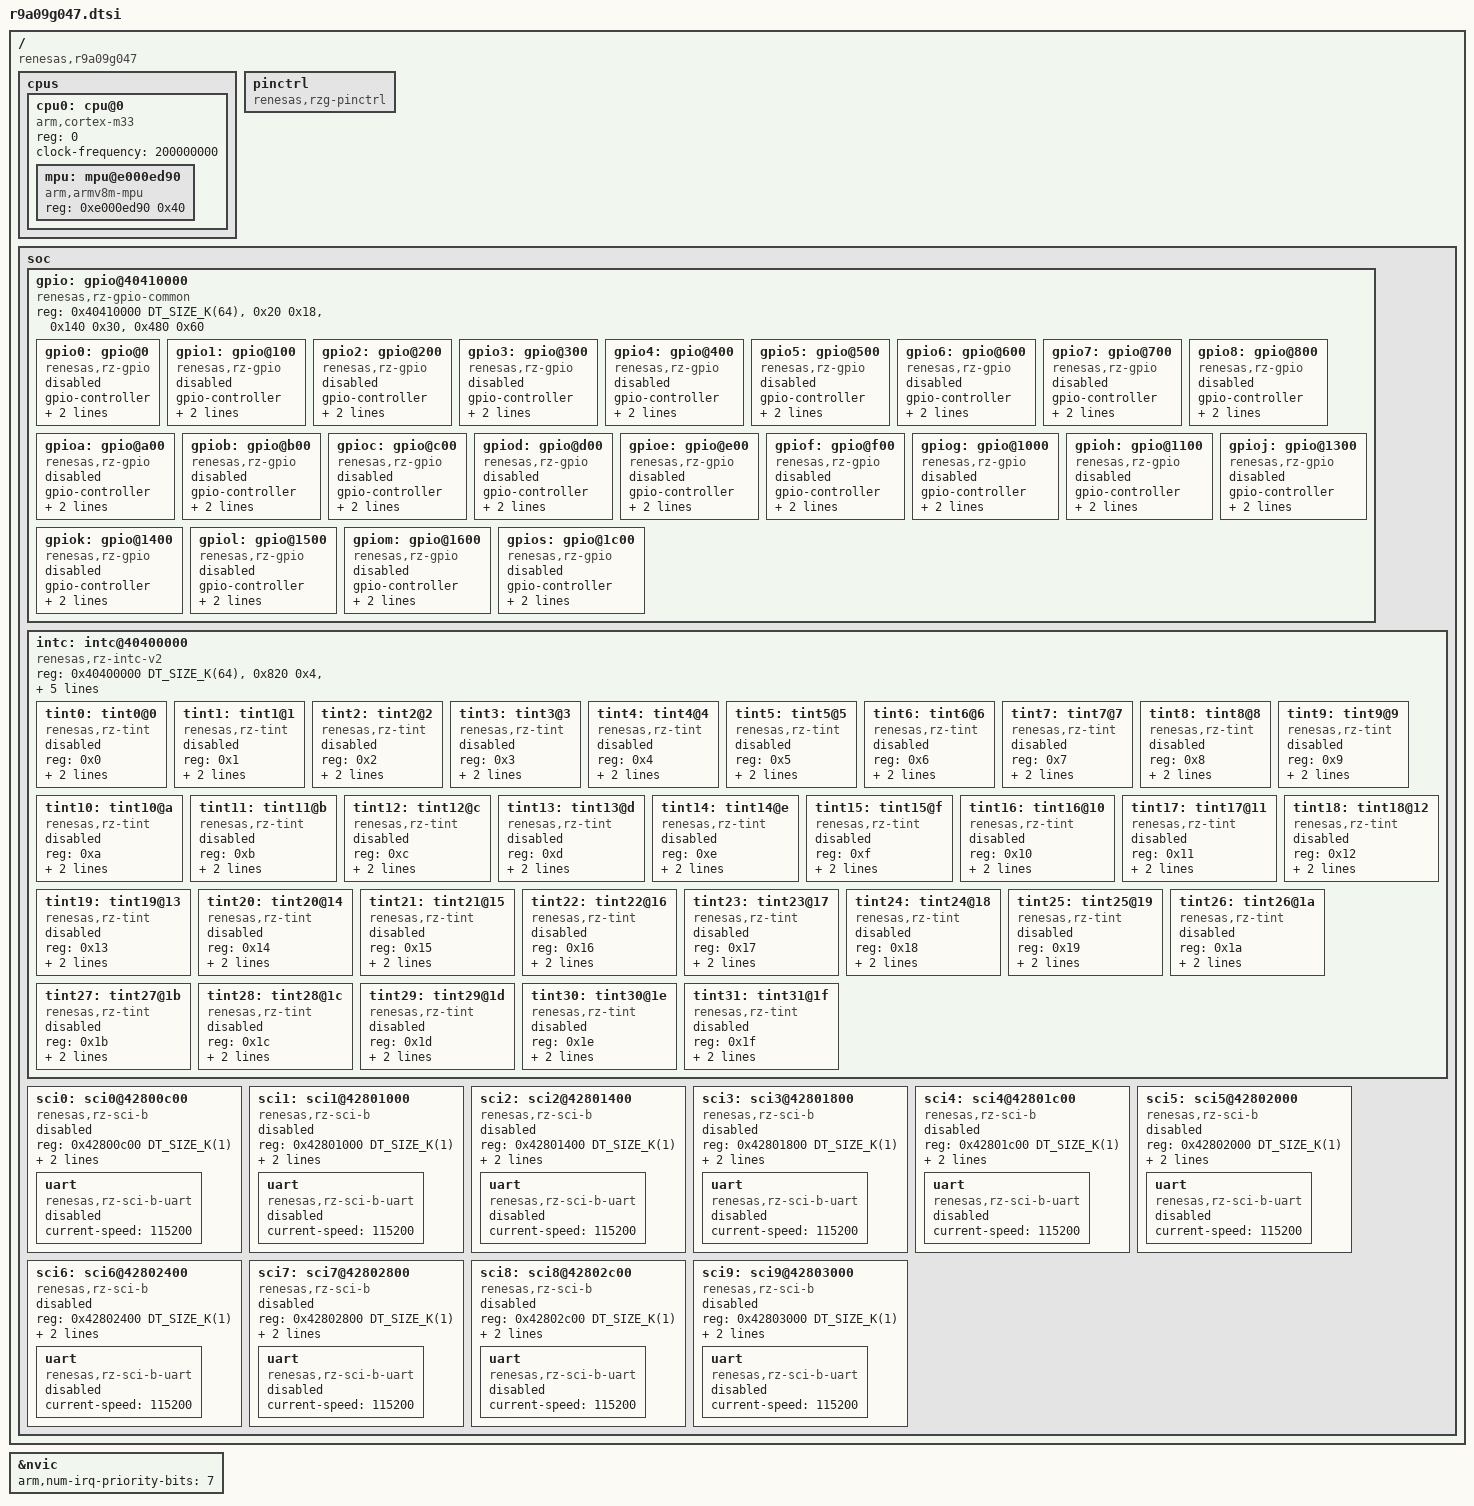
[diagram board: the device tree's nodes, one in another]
/*
 * Copyright (c) 2025 Renesas Electronics Corporation
 * SPDX-License-Identifier: Apache-2.0
 */

#include <arm/armv8-m.dtsi>
#include <mem.h>

/ {
	compatible = "renesas,r9a09g047";
	#address-cells = <1>;
	#size-cells = <1>;

	cpus {
		#address-cells = <1>;
		#size-cells = <0>;

		cpu0: cpu@0 {
			device_type = "cpu";
			compatible = "arm,cortex-m33";
			reg = <0>;
			clock-frequency = <200000000>;
			#address-cells = <1>;
			#size-cells = <1>;

			mpu: mpu@e000ed90 {
				compatible = "arm,armv8m-mpu";
				reg = <0xe000ed90 0x40>;
			};
		};
	};

	/* Dummy pinctrl node, filled with pin mux options at board level */
	pinctrl: pinctrl {
		compatible = "renesas,rzg-pinctrl";
	};

	soc {
		gpio: gpio@40410000 {
			compatible = "renesas,rz-gpio-common";
			reg = <0x40410000 DT_SIZE_K(64)>,
			      <0x20 0x18>,
			      <0x140 0x30>,
			      <0x480 0x60>;
			reg-names = "base", "p", "pm", "pfc";
			#address-cells = <1>;
			#size-cells = <0>;

			gpio0: gpio@0 {
				compatible = "renesas,rz-gpio";
				gpio-controller;
				#gpio-cells = <2>;
				ngpios = <8>;
				reg = <0x0>;
				status = "disabled";
			};

			gpio1: gpio@100 {
				compatible = "renesas,rz-gpio";
				gpio-controller;
				#gpio-cells = <2>;
				ngpios = <8>;
				reg = <0x100>;
				status = "disabled";
			};

			gpio2: gpio@200 {
				compatible = "renesas,rz-gpio";
				gpio-controller;
				#gpio-cells = <2>;
				ngpios = <2>;
				reg = <0x200>;
				status = "disabled";
			};

			gpio3: gpio@300 {
				compatible = "renesas,rz-gpio";
				gpio-controller;
				#gpio-cells = <2>;
				ngpios = <8>;
				reg = <0x300>;
				status = "disabled";
			};

			gpio4: gpio@400 {
				compatible = "renesas,rz-gpio";
				gpio-controller;
				#gpio-cells = <2>;
				ngpios = <6>;
				reg = <0x400>;
				status = "disabled";
			};

			gpio5: gpio@500 {
				compatible = "renesas,rz-gpio";
				gpio-controller;
				#gpio-cells = <2>;
				ngpios = <7>;
				reg = <0x500>;
				status = "disabled";
			};

			gpio6: gpio@600 {
				compatible = "renesas,rz-gpio";
				gpio-controller;
				#gpio-cells = <2>;
				ngpios = <7>;
				reg = <0x600>;
				status = "disabled";
			};

			gpio7: gpio@700 {
				compatible = "renesas,rz-gpio";
				gpio-controller;
				#gpio-cells = <2>;
				ngpios = <8>;
				reg = <0x700>;
				status = "disabled";
			};

			gpio8: gpio@800 {
				compatible = "renesas,rz-gpio";
				gpio-controller;
				#gpio-cells = <2>;
				ngpios = <6>;
				reg = <0x800>;
				status = "disabled";
			};

			gpioa: gpio@a00 {
				compatible = "renesas,rz-gpio";
				gpio-controller;
				#gpio-cells = <2>;
				ngpios = <8>;
				reg = <0xa00>;
				status = "disabled";
			};

			gpiob: gpio@b00 {
				compatible = "renesas,rz-gpio";
				gpio-controller;
				#gpio-cells = <2>;
				ngpios = <8>;
				reg = <0xb00>;
				status = "disabled";
			};

			gpioc: gpio@c00 {
				compatible = "renesas,rz-gpio";
				gpio-controller;
				#gpio-cells = <2>;
				ngpios = <3>;
				reg = <0xc00>;
				status = "disabled";
			};

			gpiod: gpio@d00 {
				compatible = "renesas,rz-gpio";
				gpio-controller;
				#gpio-cells = <2>;
				ngpios = <8>;
				reg = <0xd00>;
				status = "disabled";
			};

			gpioe: gpio@e00 {
				compatible = "renesas,rz-gpio";
				gpio-controller;
				#gpio-cells = <2>;
				ngpios = <8>;
				reg = <0xe00>;
				status = "disabled";
			};

			gpiof: gpio@f00 {
				compatible = "renesas,rz-gpio";
				gpio-controller;
				#gpio-cells = <2>;
				ngpios = <3>;
				reg = <0xf00>;
				status = "disabled";
			};

			gpiog: gpio@1000 {
				compatible = "renesas,rz-gpio";
				gpio-controller;
				#gpio-cells = <2>;
				ngpios = <8>;
				reg = <0x1000>;
				status = "disabled";
			};

			gpioh: gpio@1100 {
				compatible = "renesas,rz-gpio";
				gpio-controller;
				#gpio-cells = <2>;
				ngpios = <6>;
				reg = <0x1100>;
				status = "disabled";
			};

			gpioj: gpio@1300 {
				compatible = "renesas,rz-gpio";
				gpio-controller;
				#gpio-cells = <2>;
				ngpios = <5>;
				reg = <0x1300>;
				status = "disabled";
			};

			gpiok: gpio@1400 {
				compatible = "renesas,rz-gpio";
				gpio-controller;
				#gpio-cells = <2>;
				ngpios = <4>;
				reg = <0x1400>;
				status = "disabled";
			};

			gpiol: gpio@1500 {
				compatible = "renesas,rz-gpio";
				gpio-controller;
				#gpio-cells = <2>;
				ngpios = <4>;
				reg = <0x1500>;
				status = "disabled";
			};

			gpiom: gpio@1600 {
				compatible = "renesas,rz-gpio";
				gpio-controller;
				#gpio-cells = <2>;
				ngpios = <8>;
				reg = <0x1600>;
				status = "disabled";
			};

			gpios: gpio@1c00 {
				compatible = "renesas,rz-gpio";
				gpio-controller;
				#gpio-cells = <2>;
				ngpios = <4>;
				reg = <0x1c00>;
				status = "disabled";
			};
		};

		intc: intc@40400000 {
			compatible = "renesas,rz-intc-v2";
			reg = <0x40400000 DT_SIZE_K(64)>,
			      <0x820 0x4>,
			      <0x828 0x4>,
			      <0x830 0x4>,
			      <0x200 0x4>;
			reg-names = "intc", "tscr", "titsr0", "tssr0", "intsel";
			gpioint-table = <81 89 111 97 105 113 120 127 135 43
					 51 59 62 70 78 25 33 4 39 9 13 0>;
			max-gpioint = <140>;
			#address-cells = <1>;
			#size-cells = <0>;
			interrupt-parent = <&nvic>;

			tint0: tint0@0 {
				compatible = "renesas,rz-tint";
				reg = <0x0>;
				interrupts = <353 1>;
				trigger-type = "rising";
				#irq-cells = <1>;
				status = "disabled";
			};

			tint1: tint1@1 {
				compatible = "renesas,rz-tint";
				reg = <0x1>;
				interrupts = <354 1>;
				trigger-type = "rising";
				#irq-cells = <1>;
				status = "disabled";
			};

			tint2: tint2@2 {
				compatible = "renesas,rz-tint";
				reg = <0x2>;
				interrupts = <355 1>;
				trigger-type = "rising";
				#irq-cells = <1>;
				status = "disabled";
			};

			tint3: tint3@3 {
				compatible = "renesas,rz-tint";
				reg = <0x3>;
				interrupts = <356 1>;
				trigger-type = "rising";
				#irq-cells = <1>;
				status = "disabled";
			};

			tint4: tint4@4 {
				compatible = "renesas,rz-tint";
				reg = <0x4>;
				interrupts = <357 1>;
				trigger-type = "rising";
				#irq-cells = <1>;
				status = "disabled";
			};

			tint5: tint5@5 {
				compatible = "renesas,rz-tint";
				reg = <0x5>;
				interrupts = <358 1>;
				trigger-type = "rising";
				#irq-cells = <1>;
				status = "disabled";
			};

			tint6: tint6@6 {
				compatible = "renesas,rz-tint";
				reg = <0x6>;
				interrupts = <359 1>;
				trigger-type = "rising";
				#irq-cells = <1>;
				status = "disabled";
			};

			tint7: tint7@7 {
				compatible = "renesas,rz-tint";
				reg = <0x7>;
				interrupts = <360 1>;
				trigger-type = "rising";
				#irq-cells = <1>;
				status = "disabled";
			};

			tint8: tint8@8 {
				compatible = "renesas,rz-tint";
				reg = <0x8>;
				interrupts = <361 1>;
				trigger-type = "rising";
				#irq-cells = <1>;
				status = "disabled";
			};

			tint9: tint9@9 {
				compatible = "renesas,rz-tint";
				reg = <0x9>;
				interrupts = <362 1>;
				trigger-type = "rising";
				#irq-cells = <1>;
				status = "disabled";
			};

			tint10: tint10@a {
				compatible = "renesas,rz-tint";
				reg = <0xa>;
				interrupts = <363 1>;
				trigger-type = "rising";
				#irq-cells = <1>;
				status = "disabled";
			};

			tint11: tint11@b {
				compatible = "renesas,rz-tint";
				reg = <0xb>;
				interrupts = <364 1>;
				trigger-type = "rising";
				#irq-cells = <1>;
				status = "disabled";
			};

			tint12: tint12@c {
				compatible = "renesas,rz-tint";
				reg = <0xc>;
				interrupts = <365 1>;
				trigger-type = "rising";
				#irq-cells = <1>;
				status = "disabled";
			};

			tint13: tint13@d {
				compatible = "renesas,rz-tint";
				reg = <0xd>;
				interrupts = <366 1>;
				trigger-type = "rising";
				#irq-cells = <1>;
				status = "disabled";
			};

			tint14: tint14@e {
				compatible = "renesas,rz-tint";
				reg = <0xe>;
				interrupts = <367 1>;
				trigger-type = "rising";
				#irq-cells = <1>;
				status = "disabled";
			};

			tint15: tint15@f {
				compatible = "renesas,rz-tint";
				reg = <0xf>;
				interrupts = <368 1>;
				trigger-type = "rising";
				#irq-cells = <1>;
				status = "disabled";
			};

			tint16: tint16@10 {
				compatible = "renesas,rz-tint";
				reg = <0x10>;
				interrupts = <369 1>;
				trigger-type = "rising";
				#irq-cells = <1>;
				status = "disabled";
			};

			tint17: tint17@11 {
				compatible = "renesas,rz-tint";
				reg = <0x11>;
				interrupts = <370 1>;
				trigger-type = "rising";
				#irq-cells = <1>;
				status = "disabled";
			};

			tint18: tint18@12 {
				compatible = "renesas,rz-tint";
				reg = <0x12>;
				interrupts = <371 1>;
				trigger-type = "rising";
				#irq-cells = <1>;
				status = "disabled";
			};

			tint19: tint19@13 {
				compatible = "renesas,rz-tint";
				reg = <0x13>;
				interrupts = <372 1>;
				trigger-type = "rising";
				#irq-cells = <1>;
				status = "disabled";
			};

			tint20: tint20@14 {
				compatible = "renesas,rz-tint";
				reg = <0x14>;
				interrupts = <373 1>;
				trigger-type = "rising";
				#irq-cells = <1>;
				status = "disabled";
			};

			tint21: tint21@15 {
				compatible = "renesas,rz-tint";
				reg = <0x15>;
				interrupts = <374 1>;
				trigger-type = "rising";
				#irq-cells = <1>;
				status = "disabled";
			};

			tint22: tint22@16 {
				compatible = "renesas,rz-tint";
				reg = <0x16>;
				interrupts = <375 1>;
				trigger-type = "rising";
				#irq-cells = <1>;
				status = "disabled";
			};

			tint23: tint23@17 {
				compatible = "renesas,rz-tint";
				reg = <0x17>;
				interrupts = <376 1>;
				trigger-type = "rising";
				#irq-cells = <1>;
				status = "disabled";
			};

			tint24: tint24@18 {
				compatible = "renesas,rz-tint";
				reg = <0x18>;
				interrupts = <377 1>;
				trigger-type = "rising";
				#irq-cells = <1>;
				status = "disabled";
			};

			tint25: tint25@19 {
				compatible = "renesas,rz-tint";
				reg = <0x19>;
				interrupts = <378 1>;
				trigger-type = "rising";
				#irq-cells = <1>;
				status = "disabled";
			};

			tint26: tint26@1a {
				compatible = "renesas,rz-tint";
				reg = <0x1a>;
				interrupts = <379 1>;
				trigger-type = "rising";
				#irq-cells = <1>;
				status = "disabled";
			};

			tint27: tint27@1b {
				compatible = "renesas,rz-tint";
				reg = <0x1b>;
				interrupts = <380 1>;
				trigger-type = "rising";
				#irq-cells = <1>;
				status = "disabled";
			};

			tint28: tint28@1c {
				compatible = "renesas,rz-tint";
				reg = <0x1c>;
				interrupts = <381 1>;
				trigger-type = "rising";
				#irq-cells = <1>;
				status = "disabled";
			};

			tint29: tint29@1d {
				compatible = "renesas,rz-tint";
				reg = <0x1d>;
				interrupts = <382 1>;
				trigger-type = "rising";
				#irq-cells = <1>;
				status = "disabled";
			};

			tint30: tint30@1e {
				compatible = "renesas,rz-tint";
				reg = <0x1e>;
				interrupts = <383 1>;
				trigger-type = "rising";
				#irq-cells = <1>;
				status = "disabled";
			};

			tint31: tint31@1f {
				compatible = "renesas,rz-tint";
				reg = <0x1f>;
				interrupts = <384 1>;
				trigger-type = "rising";
				#irq-cells = <1>;
				status = "disabled";
			};
		};

		sci0: sci0@42800c00 {
			compatible = "renesas,rz-sci-b";
			reg = <0x42800c00 DT_SIZE_K(1)>;
			channel = <0>;
			interrupts = <114 1>, <115 1>, <116 1>, <117 1>;
			interrupt-names = "eri", "rxi", "txi", "tei";
			status = "disabled";

			uart {
				compatible = "renesas,rz-sci-b-uart";
				current-speed = <115200>;
				status = "disabled";
			};
		};

		sci1: sci1@42801000 {
			compatible = "renesas,rz-sci-b";
			reg = <0x42801000 DT_SIZE_K(1)>;
			channel = <1>;
			interrupts = <120 1>, <121 1>, <122 1>, <123 1>;
			interrupt-names = "eri", "rxi", "txi", "tei";
			status = "disabled";

			uart {
				compatible = "renesas,rz-sci-b-uart";
				current-speed = <115200>;
				status = "disabled";
			};
		};

		sci2: sci2@42801400 {
			compatible = "renesas,rz-sci-b";
			reg = <0x42801400 DT_SIZE_K(1)>;
			channel = <2>;
			interrupts = <126 1>, <127 1>, <128 1>, <129 1>;
			interrupt-names = "eri", "rxi", "txi", "tei";
			status = "disabled";

			uart {
				compatible = "renesas,rz-sci-b-uart";
				current-speed = <115200>;
				status = "disabled";
			};
		};

		sci3: sci3@42801800 {
			compatible = "renesas,rz-sci-b";
			reg = <0x42801800 DT_SIZE_K(1)>;
			channel = <3>;
			interrupts = <132 1>, <133 1>, <134 1>, <135 1>;
			interrupt-names = "eri", "rxi", "txi", "tei";
			status = "disabled";

			uart {
				compatible = "renesas,rz-sci-b-uart";
				current-speed = <115200>;
				status = "disabled";
			};
		};

		sci4: sci4@42801c00 {
			compatible = "renesas,rz-sci-b";
			reg = <0x42801c00 DT_SIZE_K(1)>;
			channel = <4>;
			interrupts = <138 1>, <139 1>, <140 1>, <141 1>;
			interrupt-names = "eri", "rxi", "txi", "tei";
			status = "disabled";

			uart {
				compatible = "renesas,rz-sci-b-uart";
				current-speed = <115200>;
				status = "disabled";
			};
		};

		sci5: sci5@42802000 {
			compatible = "renesas,rz-sci-b";
			reg = <0x42802000 DT_SIZE_K(1)>;
			channel = <5>;
			interrupts = <144 1>, <145 1>, <146 1>, <147 1>;
			interrupt-names = "eri", "rxi", "txi", "tei";
			status = "disabled";

			uart {
				compatible = "renesas,rz-sci-b-uart";
				current-speed = <115200>;
				status = "disabled";
			};
		};

		sci6: sci6@42802400 {
			compatible = "renesas,rz-sci-b";
			reg = <0x42802400 DT_SIZE_K(1)>;
			channel = <6>;
			interrupts = <150 1>, <151 1>, <152 1>, <153 1>;
			interrupt-names = "eri", "rxi", "txi", "tei";
			status = "disabled";

			uart {
				compatible = "renesas,rz-sci-b-uart";
				current-speed = <115200>;
				status = "disabled";
			};
		};

		sci7: sci7@42802800 {
			compatible = "renesas,rz-sci-b";
			reg = <0x42802800 DT_SIZE_K(1)>;
			channel = <7>;
			interrupts = <156 1>, <157 1>, <158 1>, <159 1>;
			interrupt-names = "eri", "rxi", "txi", "tei";
			status = "disabled";

			uart {
				compatible = "renesas,rz-sci-b-uart";
				current-speed = <115200>;
				status = "disabled";
			};
		};

		sci8: sci8@42802c00 {
			compatible = "renesas,rz-sci-b";
			reg = <0x42802c00 DT_SIZE_K(1)>;
			channel = <8>;
			interrupts = <162 1>, <163 1>, <164 1>, <165 1>;
			interrupt-names = "eri", "rxi", "txi", "tei";
			status = "disabled";

			uart {
				compatible = "renesas,rz-sci-b-uart";
				current-speed = <115200>;
				status = "disabled";
			};
		};

		sci9: sci9@42803000 {
			compatible = "renesas,rz-sci-b";
			reg = <0x42803000 DT_SIZE_K(1)>;
			channel = <9>;
			interrupts = <168 1>, <169 1>, <170 1>, <171 1>;
			interrupt-names = "eri", "rxi", "txi", "tei";
			status = "disabled";

			uart {
				compatible = "renesas,rz-sci-b-uart";
				current-speed = <115200>;
				status = "disabled";
			};
		};
	};
};

&nvic {
	arm,num-irq-priority-bits = <7>;
};
